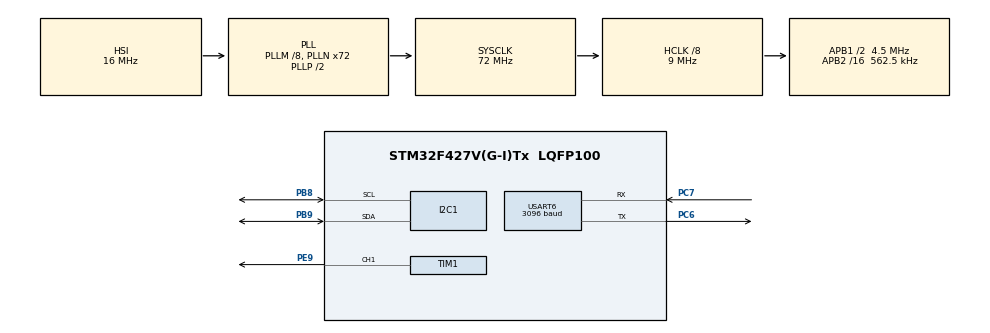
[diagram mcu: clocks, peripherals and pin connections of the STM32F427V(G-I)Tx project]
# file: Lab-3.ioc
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I2C1.I2C_Mode=I2C_Fast
Mcu.Family=STM32F4
Mcu.Name=STM32F427V(G-I)Tx
Mcu.Package=LQFP100
NVIC.PriorityGroup=NVIC_PRIORITYGROUP_4
NVIC.TIM6_DAC_IRQn=true\:0\:0\:false\:false\:true\:true\:true\:true
NVIC.USART6_IRQn=true\:0\:0\:false\:false\:true\:true\:true\:true
PA13.Mode=JTAG_5_pins
PA13.Signal=SYS_JTMS-SWDIO
PA14.Mode=JTAG_5_pins
PA14.Signal=SYS_JTCK-SWCLK
PA15.Mode=JTAG_5_pins
PA15.Signal=SYS_JTDI
PB3.Mode=JTAG_5_pins
PB3.Signal=SYS_JTDO-SWO
PB4.Mode=JTAG_5_pins
PB4.Signal=SYS_JTRST
PB8.Mode=I2C
PB8.Signal=I2C1_SCL
PB9.Mode=I2C
PB9.Signal=I2C1_SDA
PC6.Mode=Asynchronous
PC6.Signal=USART6_TX
PC7.Mode=Asynchronous
PC7.Signal=USART6_RX
PE9.Signal=S_TIM1_CH1
ProjectManager.HeapSize=0x200
ProjectManager.StackSize=0x400
ProjectManager.TargetToolchain=STM32CubeIDE
RCC.48MHZClocksFreq_Value=36000000
RCC.AHBCLKDivider=RCC_SYSCLK_DIV8
RCC.AHBFreq_Value=9000000
RCC.APB1CLKDivider=RCC_HCLK_DIV2
RCC.APB1Freq_Value=4500000
RCC.APB1TimFreq_Value=9000000
RCC.APB2CLKDivider=RCC_HCLK_DIV16
RCC.APB2Freq_Value=562500
RCC.APB2TimFreq_Value=1125000
RCC.CortexFreq_Value=9000000
RCC.HCLKFreq_Value=9000000
RCC.HSE_VALUE=25000000
RCC.HSI_VALUE=16000000
RCC.LSE_VALUE=32768
RCC.PLLM=8
RCC.PLLN=72
RCC.SYSCLKFreq_VALUE=72000000
RCC.SYSCLKSource=RCC_SYSCLKSOURCE_PLLCLK
RCC.VCOOutputFreq_Value=144000000
SH.S_TIM1_CH1.0=TIM1_CH1,PWM Generation1 CH1
TIM1.Channel-PWM\ Generation1\ CH1=TIM_CHANNEL_1
TIM1.Period=3
TIM1.Prescaler=62500
TIM1.Pulse-PWM\ Generation1\ CH1=1
TIM6.AutoReloadPreload=TIM_AUTORELOAD_PRELOAD_DISABLE
TIM6.Period=1000
TIM6.Prescaler=9000
USART6.BaudRate=3096
USART6.VirtualMode=VM_ASYNC
VP_TIM6_VS_ClockSourceINT.Mode=Enable_Timer
board=custom

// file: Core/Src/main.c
/* USER CODE BEGIN Header */
/**
 ******************************************************************************
 * @file           : main.c
 * @brief          : Main program body
 ******************************************************************************
 * @attention
 *
 * Copyright (c) 2023 STMicroelectronics.
 * All rights reserved.
 *
 * This software is licensed under terms that can be found in the LICENSE file
 * in the root directory of this software component.
 * If no LICENSE file comes with this software, it is provided AS-IS.
 *
 ******************************************************************************
 */
/* USER CODE END Header */
#include "main.h"
#include "i2c.h"
#include "tim.h"
#include "usart.h"
#include "gpio.h"

/* USER CODE BEGIN Includes */
#include "my_logic.h"
#include "my_sound.h"
#include "my_uart.h"
#include "kb.h"
#include "pca9538.h"

/* USER CODE END Includes */

void SystemClock_Config(void);

int main(void)
{

  /* MCU Configuration--------------------------------------------------------*/

  /* Reset of all peripherals, Initializes the Flash interface and the Systick. */
  HAL_Init();

  /* Configure the system clock */
  SystemClock_Config();

  /* Initialize all configured peripherals */
  MX_GPIO_Init();
  MX_USART6_UART_Init();
  MX_TIM1_Init();
  MX_TIM6_Init();
  MX_I2C1_Init();
  /* USER CODE BEGIN 2 */
	set_default_value_for_sound();
	set_default_value_for_uart();

  /* USER CODE END 2 */

  /* Infinite loop */
  /* USER CODE BEGIN WHILE */
	while (1) {
		parse_mode();
		send_message_by_uart_if_available();
    /* USER CODE END WHILE */

	}
}

void SystemClock_Config(void)
{
  RCC_OscInitTypeDef RCC_OscInitStruct = {0};
  RCC_ClkInitTypeDef RCC_ClkInitStruct = {0};

  /** Configure the main internal regulator output voltage
  */
  __HAL_RCC_PWR_CLK_ENABLE();
  __HAL_PWR_VOLTAGESCALING_CONFIG(PWR_REGULATOR_VOLTAGE_SCALE3);

  /** Initializes the RCC Oscillators according to the specified parameters
  * in the RCC_OscInitTypeDef structure.
  */
  RCC_OscInitStruct.OscillatorType = RCC_OSCILLATORTYPE_HSI;
  RCC_OscInitStruct.HSIState = RCC_HSI_ON;
  RCC_OscInitStruct.HSICalibrationValue = RCC_HSICALIBRATION_DEFAULT;
  RCC_OscInitStruct.PLL.PLLState = RCC_PLL_ON;
  RCC_OscInitStruct.PLL.PLLSource = RCC_PLLSOURCE_HSI;
  RCC_OscInitStruct.PLL.PLLM = 8;
  RCC_OscInitStruct.PLL.PLLN = 72;
  RCC_OscInitStruct.PLL.PLLP = RCC_PLLP_DIV2;
  RCC_OscInitStruct.PLL.PLLQ = 4;
  if (HAL_RCC_OscConfig(&RCC_OscInitStruct) != HAL_OK)
  {
    Error_Handler();
  }

  /** Initializes the CPU, AHB and APB buses clocks
  */
  RCC_ClkInitStruct.ClockType = RCC_CLOCKTYPE_HCLK|RCC_CLOCKTYPE_SYSCLK
                              |RCC_CLOCKTYPE_PCLK1|RCC_CLOCKTYPE_PCLK2;
  RCC_ClkInitStruct.SYSCLKSource = RCC_SYSCLKSOURCE_PLLCLK;
  RCC_ClkInitStruct.AHBCLKDivider = RCC_SYSCLK_DIV8;
  RCC_ClkInitStruct.APB1CLKDivider = RCC_HCLK_DIV2;
  RCC_ClkInitStruct.APB2CLKDivider = RCC_HCLK_DIV16;

  if (HAL_RCC_ClockConfig(&RCC_ClkInitStruct, FLASH_LATENCY_0) != HAL_OK)
  {
    Error_Handler();
  }
}

void Error_Handler(void)
{
	__disable_irq();
	while (1) {
	}
}
